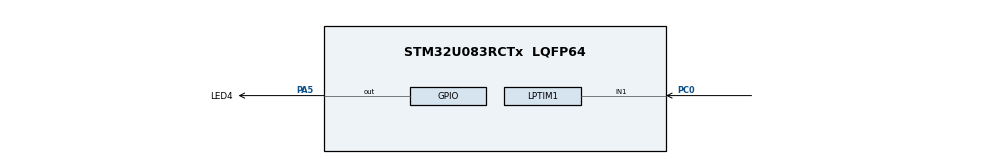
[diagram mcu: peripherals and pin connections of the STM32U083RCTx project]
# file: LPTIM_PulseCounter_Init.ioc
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LPTIM1.Period=1000
Mcu.Family=STM32U0
Mcu.Name=STM32U083RCTx
Mcu.Package=LQFP64
NVIC.PriorityGroup=NVIC_PRIORITYGROUP_2
NVIC.TIM6_DAC_LPTIM1_IRQn=true\:0\:0\:false\:false\:true\:true\:true\:true
PA5.GPIO_Label=LED4
PA5.Signal=GPIO_Output
PC0.Mode=Counts_external_clock_with_synchro_01_occur1
PC0.Signal=LPTIM1_IN1
ProjectManager.HeapSize=0x200
ProjectManager.StackSize=0x400
ProjectManager.TargetToolchain=EWARM V9.20
RCC.ADCFreq_Value=48000000
RCC.AHBFreq_Value=48000000
RCC.CodegenConfigPeriph=false
RCC.CortexFreq_Value=48000000
RCC.HCLKFreq_Value=48000000
RCC.HSE_VALUE=4000000
RCC.HSI48_VALUE=48000000
RCC.HSI_VALUE=16000000
RCC.LPTIM1CLockSelection=RCC_LPTIM1CLKSOURCE_LSI
RCC.LSE_VALUE=32768
RCC.MSIClockRangeVal=RCC_MSIRANGE_11
RCC.MSI_VALUE=48000000
RCC.PLLM=RCC_PLLM_DIV8
RCC.PLLN=8
RCC.PLLSourceVirtual=RCC_PLLSOURCE_MSI
RCC.SYSCLKFreq_VALUE=48000000
RCC.SYSCLKSource=RCC_SYSCLKSOURCE_MSI
RCC.USBFreq_Value=48000000
RCC.VCOOutputFreq_Value=48000000
VP_LPTIM1_VS_CH1.Mode=Channel_1_Active
VP_LPTIM1_VS_noIO1.Mode=NoIO_Channel_1_Active
VP_PWR_VS_SECSignals.Mode=Security/Privilege
board=custom

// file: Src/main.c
/* USER CODE BEGIN Header */
/**
  ******************************************************************************
  * @file    Examples_LL/LPTIM/LPTIM_PulseCounter_Init/Src/main.c
  * @author  MCD Application Team
  * @brief   This example describes how to use the LPTIM in counter mode
  *          using the STM32U0xx LPTIM LL API.
  *          Peripheral initialization done using LL initialization function.
  ******************************************************************************
  * @attention
  *
  * Copyright (c) 2023 STMicroelectronics.
  * All rights reserved.
  *
  * This software is licensed under terms that can be found in the LICENSE file
  * in the root directory of this software component.
  * If no LICENSE file comes with this software, it is provided AS-IS.
  *
  ******************************************************************************
  */
/* USER CODE END Header */
#include "main.h"

void SystemClock_Config(void);
static void MX_GPIO_Init(void);
static void MX_LPTIM1_Init(void);
/* USER CODE BEGIN PFP */
void EnterStop1Mode(void);
/* USER CODE END PFP */

int main(void)
{

  /* MCU Configuration--------------------------------------------------------*/

  /* Reset of all peripherals, Initializes the Flash interface and the Systick. */
  LL_APB1_GRP1_EnableClock(LL_APB1_GRP1_PERIPH_PWR);
  LL_APB1_GRP2_EnableClock(LL_APB1_GRP2_PERIPH_SYSCFG);

  /* System interrupt init*/
  NVIC_SetPriorityGrouping(NVIC_PRIORITYGROUP_2);

  /* USER CODE BEGIN Init */
  LL_APB1_GRP1_EnableClock(LL_APB1_GRP1_PERIPH_PWR);
  /* USER CODE END Init */

  /* Configure the system clock */
  SystemClock_Config();

  /* Initialize all configured peripherals */
  MX_GPIO_Init();
  MX_LPTIM1_Init();
  /* USER CODE BEGIN 2 */

  /* Enter STOP 1 mode */
  EnterStop1Mode();

  /* USER CODE END 2 */

  /* Infinite loop */
  while (1)
  {

  }
}

void SystemClock_Config(void)
{
  LL_FLASH_SetLatency(LL_FLASH_LATENCY_1);
  while(LL_FLASH_GetLatency() != LL_FLASH_LATENCY_1)
  {
  }

  LL_PWR_SetRegulVoltageScaling(LL_PWR_REGU_VOLTAGE_SCALE1);
  while (LL_PWR_IsActiveFlag_VOS() != 0)
  {
  }
  LL_PWR_EnableBkUpAccess();
  while (LL_PWR_IsEnabledBkUpAccess () == 0U)
  {
  }

  LL_RCC_LSI_Enable();

   /* Wait till LSI is ready */
  while(LL_RCC_LSI_IsReady() != 1)
  {
  }

  LL_RCC_MSI_Enable();

   /* Wait till MSI is ready */
  while(LL_RCC_MSI_IsReady() != 1)
  {
  }

  LL_RCC_MSI_EnableRangeSelection();
  LL_RCC_MSI_SetRange(LL_RCC_MSIRANGE_11);
  LL_RCC_SetSysClkSource(LL_RCC_SYS_CLKSOURCE_MSI);

   /* Wait till System clock is ready */
  while(LL_RCC_GetSysClkSource() != LL_RCC_SYS_CLKSOURCE_STATUS_MSI)
  {
  }

  LL_RCC_SetAHBPrescaler(LL_RCC_SYSCLK_DIV_1);
  LL_RCC_SetAPB1Prescaler(LL_RCC_APB1_DIV_1);

  LL_Init1msTick(48000000);

  LL_SetSystemCoreClock(48000000);
}

static void MX_LPTIM1_Init(void)
{

  LL_GPIO_InitTypeDef GPIO_InitStruct = {0};

  LL_RCC_SetLPTIMClockSource(LL_RCC_LPTIM1_CLKSOURCE_LSI);

  /* Peripheral clock enable */
  LL_APB1_GRP1_EnableClock(LL_APB1_GRP1_PERIPH_LPTIM1);

  LL_IOP_GRP1_EnableClock(LL_IOP_GRP1_PERIPH_GPIOC);
  /**LPTIM1 GPIO Configuration
  PC0   ------> LPTIM1_IN1
  */
  GPIO_InitStruct.Pin = LL_GPIO_PIN_0;
  GPIO_InitStruct.Mode = LL_GPIO_MODE_ALTERNATE;
  GPIO_InitStruct.Speed = LL_GPIO_SPEED_FREQ_LOW;
  GPIO_InitStruct.OutputType = LL_GPIO_OUTPUT_PUSHPULL;
  GPIO_InitStruct.Pull = LL_GPIO_PULL_NO;
  GPIO_InitStruct.Alternate = LL_GPIO_AF_1;
  LL_GPIO_Init(GPIOC, &GPIO_InitStruct);

  /* LPTIM1 interrupt Init */
  NVIC_SetPriority(TIM6_DAC_LPTIM1_IRQn, NVIC_EncodePriority(NVIC_GetPriorityGrouping(),0, 0));
  NVIC_EnableIRQ(TIM6_DAC_LPTIM1_IRQn);

  /* USER CODE BEGIN LPTIM1_Init 1 */

  /* LPTIM1 interrupts set-up */
  /* Enable the Autoreload match Interrupt */
  LL_LPTIM_EnableIT_ARRM(LPTIM1);

  /* USER CODE END LPTIM1_Init 1 */
  LL_LPTIM_Enable(LPTIM1);
  LL_LPTIM_ClearFlag_REPOK(LPTIM1);
  LL_LPTIM_SetRepetition(LPTIM1, 0);

   /* Wait till REPOK Flag is ready */
  while(!LL_LPTIM_IsActiveFlag_REPOK(LPTIM1))
  {
  }
  LL_LPTIM_ClearFlag_ARROK(LPTIM1);
  LL_LPTIM_SetAutoReload(LPTIM1, 1000);

   /* Wait till ARROK Flag is ready */
  while(!LL_LPTIM_IsActiveFlag_ARROK(LPTIM1))
  {
  }
  LL_LPTIM_Disable(LPTIM1);
  LL_LPTIM_SetClockSource(LPTIM1, LL_LPTIM_CLK_SOURCE_INTERNAL);
  LL_LPTIM_SetPrescaler(LPTIM1, LL_LPTIM_PRESCALER_DIV1);
  LL_LPTIM_SetUpdateMode(LPTIM1, LL_LPTIM_UPDATE_MODE_IMMEDIATE);
  LL_LPTIM_SetCounterMode(LPTIM1, LL_LPTIM_COUNTER_MODE_EXTERNAL);
  LL_LPTIM_ConfigClock(LPTIM1, LL_LPTIM_CLK_FILTER_NONE, LL_LPTIM_CLK_POLARITY_RISING);
  LL_LPTIM_TrigSw(LPTIM1);
  LL_LPTIM_SetInput1Src(LPTIM1, LL_LPTIM_INPUT1_SRC_GPIO);
  LL_LPTIM_SetInput2Src(LPTIM1, LL_LPTIM_INPUT2_SRC_GPIO);
  LL_LPTIM_IC_SetPolarity(LPTIM1, LL_LPTIM_CHANNEL_CH1, LL_LPTIM_ICPOLARITY_RISING);
  LL_LPTIM_IC_SetFilter(LPTIM1, LL_LPTIM_CHANNEL_CH1, LL_LPTIM_ICFLT_CLOCK_DIV1);
  LL_LPTIM_IC_SetPrescaler(LPTIM1, LL_LPTIM_CHANNEL_CH1, LL_LPTIM_ICPSC_DIV1);
  /* USER CODE BEGIN LPTIM1_Init 2 */

  /* Enable the LPTIM1 counter */
  LL_LPTIM_Enable(LPTIM1);

  /* Set the Autoreload value */
  LL_LPTIM_SetAutoReload(LPTIM1, 1000);

  /* Start the LPTIM counter in continuous mode */
  LL_LPTIM_StartCounter(LPTIM1, LL_LPTIM_OPERATING_MODE_CONTINUOUS);

  /* USER CODE END LPTIM1_Init 2 */

}

static void MX_GPIO_Init(void)
{
  LL_GPIO_InitTypeDef GPIO_InitStruct = {0};

  /* GPIO Ports Clock Enable */
  LL_IOP_GRP1_EnableClock(LL_IOP_GRP1_PERIPH_GPIOC);
  LL_IOP_GRP1_EnableClock(LL_IOP_GRP1_PERIPH_GPIOA);

  /**/
  LL_GPIO_ResetOutputPin(LED4_GPIO_Port, LED4_Pin);

  /**/
  GPIO_InitStruct.Pin = LED4_Pin;
  GPIO_InitStruct.Mode = LL_GPIO_MODE_OUTPUT;
  GPIO_InitStruct.Speed = LL_GPIO_SPEED_FREQ_LOW;
  GPIO_InitStruct.OutputType = LL_GPIO_OUTPUT_PUSHPULL;
  GPIO_InitStruct.Pull = LL_GPIO_PULL_NO;
  LL_GPIO_Init(LED4_GPIO_Port, &GPIO_InitStruct);

}

/* USER CODE BEGIN 4 */

/**
  * @brief  Function to configure and enter in STOP 1 Mode.
  * @param  None
  * @retval None
  */
void EnterStop1Mode(void)
{
  /* Set low-power mode "Stop" */
  LL_PWR_SetPowerMode(LL_PWR_MODE_STOP1);

  /* Set SLEEPDEEP bit of Cortex System Control Register */
  LL_LPM_EnableDeepSleep();

  /* Request Wait For Interrupt */
  __WFI();
}

/******************************************************************************/
/*   USER IRQ HANDLER TREATMENT                                               */
/******************************************************************************/
/**
  * @brief  LPTimer Autoreload match interrupt processing
  * @param  None
  * @retval None
  */
void LPTimerAutoreloadMatch_Callback(void)
{
  LL_GPIO_TogglePin(LED4_GPIO_Port, LED4_Pin);
  LL_mDelay(1000);
}

/* USER CODE END 4 */

void Error_Handler(void)
{
}
